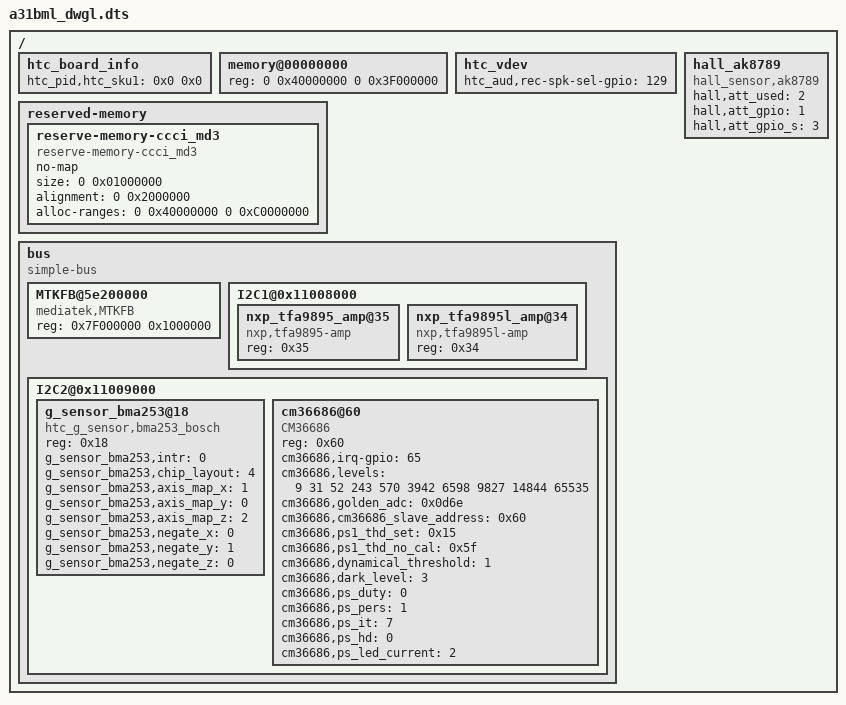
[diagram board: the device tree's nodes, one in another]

/dts-v1/;

/include/ "mt6753.dtsi"
/include/ "htc_features.dtsi"
/include/ "mt6753-touch-a31bml.dtsi"

/ {
	htc_board_info {
		        htc_pid,htc_sku1 = <0x0 0x0>;
	};

 	memory@00000000 {
		device_type = "memory";
		reg = <0 0x40000000 0 0x3F000000>;
	};

        htc_vdev{
                htc_aud,rec-spk-sel-gpio = <129>;
        };

	reserved-memory {
		#address-cells = <2>;
		#size-cells = <2>;
		ranges;

		reserve-memory-ccci_md3 {
			compatible = "reserve-memory-ccci_md3";
			no-map;
			size = <0 0x01000000>;
			alignment = <0 0x2000000>;
			alloc-ranges = <0 0x40000000 0 0xC0000000>;
		};
	};

	bus {
		compatible = "simple-bus";
		#address-cells = <1>;
		#size-cells = <1>;
		ranges = <0 0 0 0xffffffff>;

		MTKFB@5e200000 {
			compatible = "mediatek,MTKFB";
			reg = <0x7F000000 0x1000000>;
		};

                I2C1@0x11008000 {
                        status = "ok";

                        nxp_tfa9895_amp@35 {
                                compatible = "nxp,tfa9895-amp";
                                reg = <0x35>;
                        };

                        nxp_tfa9895l_amp@34 {
                                compatible = "nxp,tfa9895l-amp";
                                reg = <0x34>;
                        };
                };
		I2C2@0x11009000 {
			g_sensor_bma253@18 {
				compatible = "htc_g_sensor,bma253_bosch";
				reg = <0x18>;
				g_sensor_bma253,intr        = <0>;
				g_sensor_bma253,chip_layout = <4>;
				g_sensor_bma253,axis_map_x  = <1>;
				g_sensor_bma253,axis_map_y  = <0>;
				g_sensor_bma253,axis_map_z  = <2>;
				g_sensor_bma253,negate_x    = <0>;
				g_sensor_bma253,negate_y    = <1>;
				g_sensor_bma253,negate_z    = <0>;
			};
			cm36686@60 {
			compatible = "CM36686";
			reg = <0x60>;
			cm36686,irq-gpio = <65>;
			cm36686,levels = <9 31 52 243 570 3942 6598 9827 14844 65535>;
			cm36686,golden_adc = <0x0d6e>;
			cm36686,cm36686_slave_address = <0x60>;
			cm36686,ps1_thd_set = <0x15>;
			cm36686,ps1_thd_no_cal = <0x5f>;
			cm36686,dynamical_threshold = <1>;
			cm36686,dark_level = <3>;
			cm36686,ps_duty = <0>;
			cm36686,ps_pers = <1>;
			cm36686,ps_it = <7>;
			cm36686,ps_hd = <0>;
			cm36686,ps_led_current = <2>;
			};
		};
	};
	hall_ak8789 {
		compatible = "hall_sensor,ak8789";
		hall,att_used = <2>;
		hall,att_gpio = <1>;
		hall,att_gpio_s = <3>;
	};
};
